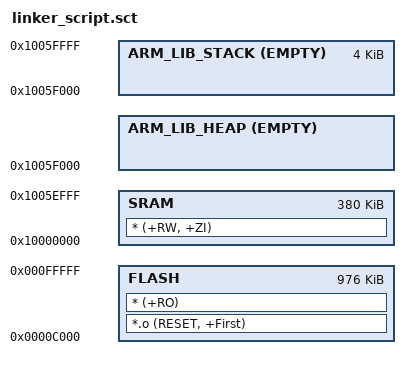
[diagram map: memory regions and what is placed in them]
;******************************************************************************
;
; binary_counter.sct
;
; Scatter file for Keil linker configuration.
;
;******************************************************************************

;******************************************************************************
;
; Copyright (c) 2024, Ambiq Micro, Inc.
; All rights reserved.
;
; Redistribution and use in source and binary forms, with or without
; modification, are permitted provided that the following conditions are met:
;
; 1. Redistributions of source code must retain the above copyright notice,
; this list of conditions and the following disclaimer.
;
; 2. Redistributions in binary form must reproduce the above copyright
; notice, this list of conditions and the following disclaimer in the
; documentation and/or other materials provided with the distribution.
;
; 3. Neither the name of the copyright holder nor the names of its
; contributors may be used to endorse or promote products derived from this
; software without specific prior written permission.
;
; Third party software included in this distribution is subject to the
; additional license terms as defined in the /docs/licenses directory.
;
; THIS SOFTWARE IS PROVIDED BY THE COPYRIGHT HOLDERS AND CONTRIBUTORS "AS IS"
; AND ANY EXPRESS OR IMPLIED WARRANTIES, INCLUDING, BUT NOT LIMITED TO, THE
; IMPLIED WARRANTIES OF MERCHANTABILITY AND FITNESS FOR A PARTICULAR PURPOSE
; ARE DISCLAIMED. IN NO EVENT SHALL THE COPYRIGHT HOLDER OR CONTRIBUTORS BE
; LIABLE FOR ANY DIRECT, INDIRECT, INCIDENTAL, SPECIAL, EXEMPLARY, OR
; CONSEQUENTIAL DAMAGES (INCLUDING, BUT NOT LIMITED TO, PROCUREMENT OF
; SUBSTITUTE GOODS OR SERVICES; LOSS OF USE, DATA, OR PROFITS; OR BUSINESS
; INTERRUPTION) HOWEVER CAUSED AND ON ANY THEORY OF LIABILITY, WHETHER IN
; CONTRACT, STRICT LIABILITY, OR TORT (INCLUDING NEGLIGENCE OR OTHERWISE)
; ARISING IN ANY WAY OUT OF THE USE OF THIS SOFTWARE, EVEN IF ADVISED OF THE
; POSSIBILITY OF SUCH DAMAGE.
;
; This is part of revision release_sdk_3_2_0-dd5f40c14b of the AmbiqSuite Development Package.
;
;******************************************************************************
LR_1 0x0000C000
{
    FLASH 0x0000C000 0x000F4000
    {
        *.o (RESET, +First)
        * (+RO)
    }

    ; RW + ZI at the base of SRAM.  Bounded to leave the top 4 KB for the
    ; C-library stack region below (matching the legacy startup's 4 KB stack
    ; and zero-length heap).
    SRAM 0x10000000 0x0005F000
    {
        * (+RW, +ZI)
    }

    ; Zero-length heap (the legacy startup reserved no heap).  Placed at the
    ; stack-region base so the C library has a defined, non-overlapping heap.
    ARM_LIB_HEAP 0x1005F000 EMPTY 0x00000000
    {
    }

    ; 4 KB stack growing down from 0x10060000 (top of SRAM).  __INITIAL_SP
    ; (Image$$ARM_LIB_STACK$$ZI$$Limit) resolves to 0x10060000.
    ARM_LIB_STACK 0x10060000 EMPTY -0x00001000
    {
    }
}
